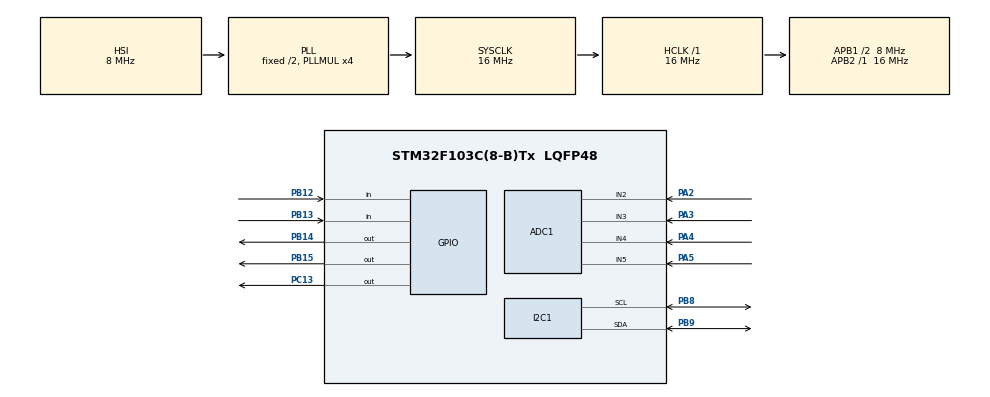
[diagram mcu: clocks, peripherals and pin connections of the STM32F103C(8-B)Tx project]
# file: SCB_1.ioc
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ADC1.Channel-0\#ChannelRegularConversion=ADC_CHANNEL_2
ADC1.Channel-1\#ChannelRegularConversion=ADC_CHANNEL_3
ADC1.Channel-7\#ChannelRegularConversion=ADC_CHANNEL_4
ADC1.Channel-8\#ChannelRegularConversion=ADC_CHANNEL_5
ADC1.ContinuousConvMode=DISABLE
ADC1.NbrOfConversion=4
ADC1.NbrOfConversionFlag=1
ADC1.Rank-0\#ChannelRegularConversion=1
ADC1.Rank-1\#ChannelRegularConversion=2
ADC1.Rank-7\#ChannelRegularConversion=3
ADC1.Rank-8\#ChannelRegularConversion=4
ADC1.SamplingTime-0\#ChannelRegularConversion=ADC_SAMPLETIME_71CYCLES_5
ADC1.SamplingTime-1\#ChannelRegularConversion=ADC_SAMPLETIME_71CYCLES_5
ADC1.SamplingTime-7\#ChannelRegularConversion=ADC_SAMPLETIME_71CYCLES_5
ADC1.SamplingTime-8\#ChannelRegularConversion=ADC_SAMPLETIME_71CYCLES_5
ADC1.master=1
Dma.ADC1.0.Direction=DMA_PERIPH_TO_MEMORY
Dma.ADC1.0.Instance=DMA1_Channel1
Dma.ADC1.0.MemDataAlignment=DMA_MDATAALIGN_WORD
Dma.ADC1.0.MemInc=DMA_MINC_ENABLE
Dma.ADC1.0.Mode=DMA_NORMAL
Dma.ADC1.0.PeriphDataAlignment=DMA_PDATAALIGN_WORD
Dma.ADC1.0.PeriphInc=DMA_PINC_DISABLE
Dma.ADC1.0.Priority=DMA_PRIORITY_LOW
Dma.Request0=ADC1
I2C1.I2C_Mode=I2C_Fast
IWDG.Prescaler=IWDG_PRESCALER_256
Mcu.Family=STM32F1
Mcu.Name=STM32F103C(8-B)Tx
Mcu.Package=LQFP48
NVIC.DMA1_Channel1_IRQn=true\:5\:0\:true\:true\:true\:1\:false\:true\:true
NVIC.PriorityGroup=NVIC_PRIORITYGROUP_4
NVIC.TIM2_IRQn=true\:2\:0\:true\:true\:true\:2\:true\:true\:true
PA13.Mode=Serial_Wire
PA13.Signal=SYS_JTMS-SWDIO
PA14.Mode=Serial_Wire
PA14.Signal=SYS_JTCK-SWCLK
PA2.Signal=ADCx_IN2
PA3.Signal=ADCx_IN3
PA4.Signal=ADCx_IN4
PA5.Signal=ADCx_IN5
PB12.Signal=GPIO_Input
PB13.Signal=GPIO_Input
PB14.Signal=GPIO_Output
PB15.Signal=GPIO_Output
PB8.Mode=I2C
PB8.Signal=I2C1_SCL
PB9.Mode=I2C
PB9.Signal=I2C1_SDA
PC13-TAMPER-RTC.Signal=GPIO_Output
ProjectManager.HeapSize=0x400
ProjectManager.StackSize=0x800
ProjectManager.TargetToolchain=MDK-ARM V5.32
RCC.AHBFreq_Value=16000000
RCC.APB1CLKDivider=RCC_HCLK_DIV2
RCC.APB1Freq_Value=8000000
RCC.APB1TimFreq_Value=16000000
RCC.APB2Freq_Value=16000000
RCC.APB2TimFreq_Value=16000000
RCC.HCLKFreq_Value=16000000
RCC.PLLMUL=RCC_PLL_MUL4
RCC.SYSCLKFreq_VALUE=16000000
RCC.SYSCLKSource=RCC_SYSCLKSOURCE_PLLCLK
RCC.USBFreq_Value=16000000
SH.ADCx_IN2.0=ADC1_IN2,IN2
SH.ADCx_IN3.0=ADC1_IN3,IN3
SH.ADCx_IN4.0=ADC1_IN4,IN4
SH.ADCx_IN5.0=ADC1_IN5,IN5
TIM2.AutoReloadPreload=TIM_AUTORELOAD_PRELOAD_DISABLE
TIM2.Period=5999
TIM2.Prescaler=15999
VP_IWDG_VS_IWDG.Mode=IWDG_Activate
VP_TIM2_VS_ClockSourceINT.Mode=Internal
board=custom

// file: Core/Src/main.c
/* USER CODE BEGIN Header */
/**
  ******************************************************************************
  * @file           : main.c
  * @brief          : Main program body
  ******************************************************************************
  * @attention
  *
  * Copyright (c) 2025 STMicroelectronics.
  * All rights reserved.
  *
  * This software is licensed under terms that can be found in the LICENSE file
  * in the root directory of this software component.
  * If no LICENSE file comes with this software, it is provided AS-IS.
  *
  ******************************************************************************
  */
/* USER CODE END Header */
#include "main.h"

/* USER CODE BEGIN Includes */
#include "SCB_Header.h"
/* USER CODE END Includes */

ADC_HandleTypeDef hadc1;
DMA_HandleTypeDef hdma_adc1;

I2C_HandleTypeDef hi2c1;

IWDG_HandleTypeDef hiwdg;

TIM_HandleTypeDef htim2;

void SystemClock_Config(void);
static void MX_GPIO_Init(void);
static void MX_DMA_Init(void);
static void MX_ADC1_Init(void);
static void MX_TIM2_Init(void);
static void MX_IWDG_Init(void);
static void MX_I2C1_Init(void);
static void MX_NVIC_Init(void);

int main(void)
{

  /* MCU Configuration--------------------------------------------------------*/

  /* Reset of all peripherals, Initializes the Flash interface and the Systick. */
  HAL_Init();

  /* Configure the system clock */
  SystemClock_Config();

  /* Initialize all configured peripherals */
  MX_GPIO_Init();
  MX_DMA_Init();
  MX_ADC1_Init();
  MX_TIM2_Init();
  MX_IWDG_Init();
  MX_I2C1_Init();

  /* Initialize interrupts */
  MX_NVIC_Init();
  /* USER CODE BEGIN 2 */
		Init_Code();
  /* USER CODE END 2 */

  /* Infinite loop */
  while (1)
  {

    /* USER CODE BEGIN 3 */
		While_Code();
  }
  /* USER CODE END 3 */
}

void SystemClock_Config(void)
{
  RCC_OscInitTypeDef RCC_OscInitStruct = {0};
  RCC_ClkInitTypeDef RCC_ClkInitStruct = {0};
  RCC_PeriphCLKInitTypeDef PeriphClkInit = {0};

  /** Initializes the RCC Oscillators according to the specified parameters
  * in the RCC_OscInitTypeDef structure.
  */
  RCC_OscInitStruct.OscillatorType = RCC_OSCILLATORTYPE_HSI|RCC_OSCILLATORTYPE_LSI;
  RCC_OscInitStruct.HSIState = RCC_HSI_ON;
  RCC_OscInitStruct.HSICalibrationValue = RCC_HSICALIBRATION_DEFAULT;
  RCC_OscInitStruct.LSIState = RCC_LSI_ON;
  RCC_OscInitStruct.PLL.PLLState = RCC_PLL_ON;
  RCC_OscInitStruct.PLL.PLLSource = RCC_PLLSOURCE_HSI_DIV2;
  RCC_OscInitStruct.PLL.PLLMUL = RCC_PLL_MUL4;
  if (HAL_RCC_OscConfig(&RCC_OscInitStruct) != HAL_OK)
  {
    Error_Handler();
  }

  /** Initializes the CPU, AHB and APB buses clocks
  */
  RCC_ClkInitStruct.ClockType = RCC_CLOCKTYPE_HCLK|RCC_CLOCKTYPE_SYSCLK
                              |RCC_CLOCKTYPE_PCLK1|RCC_CLOCKTYPE_PCLK2;
  RCC_ClkInitStruct.SYSCLKSource = RCC_SYSCLKSOURCE_PLLCLK;
  RCC_ClkInitStruct.AHBCLKDivider = RCC_SYSCLK_DIV1;
  RCC_ClkInitStruct.APB1CLKDivider = RCC_HCLK_DIV2;
  RCC_ClkInitStruct.APB2CLKDivider = RCC_HCLK_DIV1;

  if (HAL_RCC_ClockConfig(&RCC_ClkInitStruct, FLASH_LATENCY_0) != HAL_OK)
  {
    Error_Handler();
  }
  PeriphClkInit.PeriphClockSelection = RCC_PERIPHCLK_ADC;
  PeriphClkInit.AdcClockSelection = RCC_ADCPCLK2_DIV2;
  if (HAL_RCCEx_PeriphCLKConfig(&PeriphClkInit) != HAL_OK)
  {
    Error_Handler();
  }
}

/**
  * @brief NVIC Configuration.
  * @retval None
  */
static void MX_NVIC_Init(void)
{
  /* DMA1_Channel1_IRQn interrupt configuration */
  HAL_NVIC_SetPriority(DMA1_Channel1_IRQn, 5, 0);
  HAL_NVIC_EnableIRQ(DMA1_Channel1_IRQn);
  /* TIM2_IRQn interrupt configuration */
  HAL_NVIC_SetPriority(TIM2_IRQn, 2, 0);
  HAL_NVIC_EnableIRQ(TIM2_IRQn);
}

static void MX_ADC1_Init(void)
{

  ADC_ChannelConfTypeDef sConfig = {0};

  /** Common config
  */
  hadc1.Instance = ADC1;
  hadc1.Init.ScanConvMode = ADC_SCAN_ENABLE;
  hadc1.Init.ContinuousConvMode = DISABLE;
  hadc1.Init.DiscontinuousConvMode = DISABLE;
  hadc1.Init.ExternalTrigConv = ADC_SOFTWARE_START;
  hadc1.Init.DataAlign = ADC_DATAALIGN_RIGHT;
  hadc1.Init.NbrOfConversion = 4;
  if (HAL_ADC_Init(&hadc1) != HAL_OK)
  {
    Error_Handler();
  }

  /** Configure Regular Channel
  */
  sConfig.Channel = ADC_CHANNEL_2;
  sConfig.Rank = ADC_REGULAR_RANK_1;
  sConfig.SamplingTime = ADC_SAMPLETIME_71CYCLES_5;
  if (HAL_ADC_ConfigChannel(&hadc1, &sConfig) != HAL_OK)
  {
    Error_Handler();
  }

  /** Configure Regular Channel
  */
  sConfig.Channel = ADC_CHANNEL_3;
  sConfig.Rank = ADC_REGULAR_RANK_2;
  if (HAL_ADC_ConfigChannel(&hadc1, &sConfig) != HAL_OK)
  {
    Error_Handler();
  }

  /** Configure Regular Channel
  */
  sConfig.Channel = ADC_CHANNEL_4;
  sConfig.Rank = ADC_REGULAR_RANK_3;
  if (HAL_ADC_ConfigChannel(&hadc1, &sConfig) != HAL_OK)
  {
    Error_Handler();
  }

  /** Configure Regular Channel
  */
  sConfig.Channel = ADC_CHANNEL_5;
  sConfig.Rank = ADC_REGULAR_RANK_4;
  if (HAL_ADC_ConfigChannel(&hadc1, &sConfig) != HAL_OK)
  {
    Error_Handler();
  }

}

static void MX_I2C1_Init(void)
{

  hi2c1.Instance = I2C1;
  hi2c1.Init.ClockSpeed = 400000;
  hi2c1.Init.DutyCycle = I2C_DUTYCYCLE_2;
  hi2c1.Init.OwnAddress1 = 0;
  hi2c1.Init.AddressingMode = I2C_ADDRESSINGMODE_7BIT;
  hi2c1.Init.DualAddressMode = I2C_DUALADDRESS_DISABLE;
  hi2c1.Init.OwnAddress2 = 0;
  hi2c1.Init.GeneralCallMode = I2C_GENERALCALL_DISABLE;
  hi2c1.Init.NoStretchMode = I2C_NOSTRETCH_DISABLE;
  if (HAL_I2C_Init(&hi2c1) != HAL_OK)
  {
    Error_Handler();
  }

}

static void MX_IWDG_Init(void)
{

  hiwdg.Instance = IWDG;
  hiwdg.Init.Prescaler = IWDG_PRESCALER_256;
  hiwdg.Init.Reload = 4095;
  if (HAL_IWDG_Init(&hiwdg) != HAL_OK)
  {
    Error_Handler();
  }

}

static void MX_TIM2_Init(void)
{

  TIM_ClockConfigTypeDef sClockSourceConfig = {0};
  TIM_MasterConfigTypeDef sMasterConfig = {0};

  /* USER CODE BEGIN TIM2_Init 1 */
	//15999x5999 = 6sec for 16mhz
  /* USER CODE END TIM2_Init 1 */
  htim2.Instance = TIM2;
  htim2.Init.Prescaler = 15999;
  htim2.Init.CounterMode = TIM_COUNTERMODE_UP;
  htim2.Init.Period = 5999;
  htim2.Init.ClockDivision = TIM_CLOCKDIVISION_DIV1;
  htim2.Init.AutoReloadPreload = TIM_AUTORELOAD_PRELOAD_DISABLE;
  if (HAL_TIM_Base_Init(&htim2) != HAL_OK)
  {
    Error_Handler();
  }
  sClockSourceConfig.ClockSource = TIM_CLOCKSOURCE_INTERNAL;
  if (HAL_TIM_ConfigClockSource(&htim2, &sClockSourceConfig) != HAL_OK)
  {
    Error_Handler();
  }
  sMasterConfig.MasterOutputTrigger = TIM_TRGO_RESET;
  sMasterConfig.MasterSlaveMode = TIM_MASTERSLAVEMODE_DISABLE;
  if (HAL_TIMEx_MasterConfigSynchronization(&htim2, &sMasterConfig) != HAL_OK)
  {
    Error_Handler();
  }

}

static void MX_DMA_Init(void)
{

  /* DMA controller clock enable */
  __HAL_RCC_DMA1_CLK_ENABLE();

}

static void MX_GPIO_Init(void)
{
  GPIO_InitTypeDef GPIO_InitStruct = {0};

  /* GPIO Ports Clock Enable */
  __HAL_RCC_GPIOC_CLK_ENABLE();
  __HAL_RCC_GPIOA_CLK_ENABLE();
  __HAL_RCC_GPIOB_CLK_ENABLE();

  /*Configure GPIO pin Output Level */
  HAL_GPIO_WritePin(GPIOC, GPIO_PIN_13, GPIO_PIN_RESET);

  /*Configure GPIO pin Output Level */
  HAL_GPIO_WritePin(GPIOB, GPIO_PIN_14|GPIO_PIN_15, GPIO_PIN_RESET);

  /*Configure GPIO pin : PC13 */
  GPIO_InitStruct.Pin = GPIO_PIN_13;
  GPIO_InitStruct.Mode = GPIO_MODE_OUTPUT_PP;
  GPIO_InitStruct.Pull = GPIO_NOPULL;
  GPIO_InitStruct.Speed = GPIO_SPEED_FREQ_LOW;
  HAL_GPIO_Init(GPIOC, &GPIO_InitStruct);

  /*Configure GPIO pins : PB12 PB13 */
  GPIO_InitStruct.Pin = GPIO_PIN_12|GPIO_PIN_13;
  GPIO_InitStruct.Mode = GPIO_MODE_INPUT;
  GPIO_InitStruct.Pull = GPIO_NOPULL;
  HAL_GPIO_Init(GPIOB, &GPIO_InitStruct);

  /*Configure GPIO pins : PB14 PB15 */
  GPIO_InitStruct.Pin = GPIO_PIN_14|GPIO_PIN_15;
  GPIO_InitStruct.Mode = GPIO_MODE_OUTPUT_PP;
  GPIO_InitStruct.Pull = GPIO_NOPULL;
  GPIO_InitStruct.Speed = GPIO_SPEED_FREQ_LOW;
  HAL_GPIO_Init(GPIOB, &GPIO_InitStruct);

}

void Error_Handler(void)
{
  __disable_irq();
  while (1)
  {
  }
}
